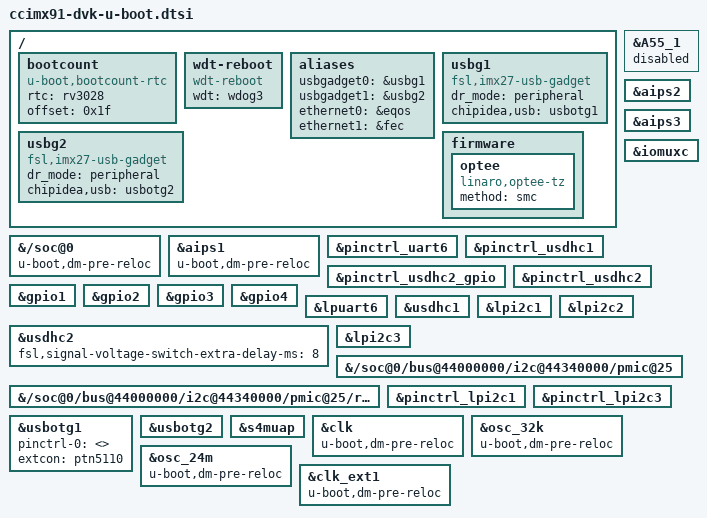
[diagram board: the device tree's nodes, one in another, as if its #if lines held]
// SPDX-License-Identifier: GPL-2.0+
/*
 * Copyright 2024 Digi International Inc
 */

/ {
	bootcount {
		compatible = "u-boot,bootcount-rtc";
		rtc = <&rv3028>;
		offset = <0x1f>;
	};

	wdt-reboot {
		compatible = "wdt-reboot";
		wdt = <&wdog3>;
		u-boot,dm-spl;
	};

	aliases {
		usbgadget0 = &usbg1;
		usbgadget1 = &usbg2;
#if defined(CONFIG_DWC_ETH_QOS)
		ethernet0 = &eqos;
		ethernet1 = &fec;
#endif
	};

	usbg1: usbg1 {
		compatible = "fsl,imx27-usb-gadget";
		dr_mode = "peripheral";
		chipidea,usb = <&usbotg1>;
		status = "okay";
	};

	usbg2: usbg2 {
		compatible = "fsl,imx27-usb-gadget";
		dr_mode = "peripheral";
		chipidea,usb = <&usbotg2>;
		status = "okay";
	};

	firmware {
		optee {
			compatible = "linaro,optee-tz";
			method = "smc";
		};
	};
};

&{/soc@0} {
	u-boot,dm-pre-reloc;
	u-boot,dm-spl;
};

&A55_1 {
	status = "disabled";
};

&aips1 {
	u-boot,dm-spl;
	u-boot,dm-pre-reloc;
};

&aips2 {
	u-boot,dm-spl;
};

&aips3 {
	u-boot,dm-spl;
};

&iomuxc {
	u-boot,dm-spl;
};

&pinctrl_uart6 {
	u-boot,dm-spl;
};

&pinctrl_usdhc1 {
	u-boot,dm-spl;
};

&pinctrl_usdhc2_gpio {
	u-boot,dm-spl;
};

&pinctrl_usdhc2 {
	u-boot,dm-spl;
};

&gpio1 {
	u-boot,dm-spl;
};

&gpio2 {
	u-boot,dm-spl;
};

&gpio3 {
	u-boot,dm-spl;
};

&gpio4 {
	u-boot,dm-spl;
};

&lpuart6 {
	u-boot,dm-spl;
};

&usdhc1 {
	u-boot,dm-spl;
};

&usdhc2 {
	u-boot,dm-spl;
	fsl,signal-voltage-switch-extra-delay-ms = <8>;
};

&lpi2c1 {
	u-boot,dm-spl;
};

&lpi2c2 {
	u-boot,dm-spl;
};

&lpi2c3 {
	u-boot,dm-spl;
};

&{/soc@0/bus@44000000/i2c@44340000/pmic@25} {
	u-boot,dm-spl;
};

&{/soc@0/bus@44000000/i2c@44340000/pmic@25/regulators} {
	u-boot,dm-spl;
};

&pinctrl_lpi2c1 {
	u-boot,dm-spl;
};

&pinctrl_lpi2c3 {
	u-boot,dm-spl;
};

&usbotg1 {
	pinctrl-names = "default";
	pinctrl-0 = <>;
	status = "okay";
	extcon = <&ptn5110>;
};

&usbotg2 {
	status = "okay";
};

&s4muap {
	u-boot,dm-spl;
	status = "okay";
};

&clk {
	u-boot,dm-pre-reloc;
	u-boot,dm-spl;
	/delete-property/ assigned-clocks;
	/delete-property/ assigned-clock-rates;
	/delete-property/ assigned-clock-parents;
};

&osc_32k {
	u-boot,dm-pre-reloc;
	u-boot,dm-spl;
};

&osc_24m {
	u-boot,dm-pre-reloc;
	u-boot,dm-spl;
};

&clk_ext1 {
	u-boot,dm-pre-reloc;
	u-boot,dm-spl;
};
